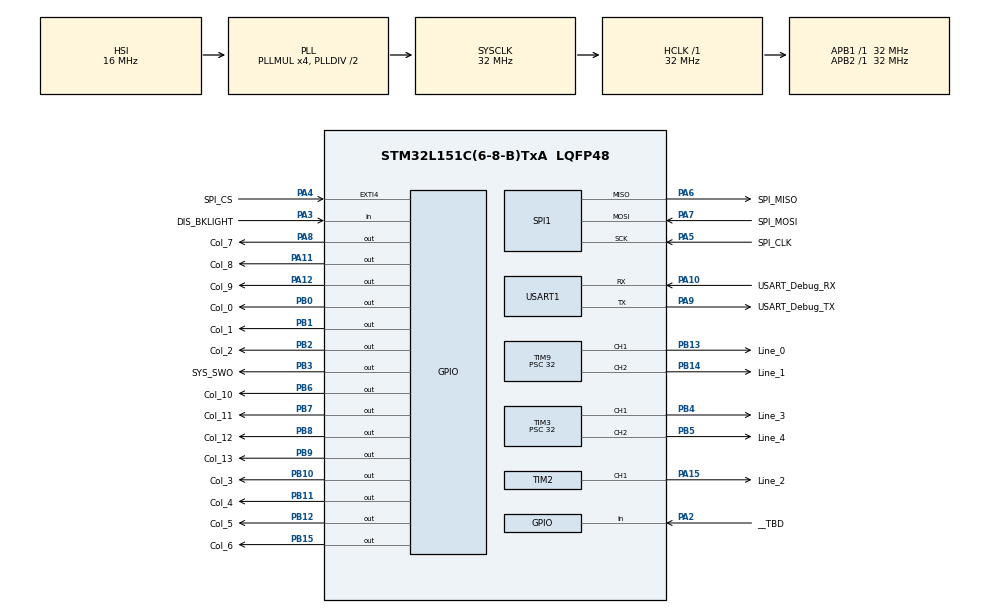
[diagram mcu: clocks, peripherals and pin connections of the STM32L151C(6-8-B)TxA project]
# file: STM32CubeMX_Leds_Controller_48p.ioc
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Dma.Request0=SPI1_RX
Dma.SPI1_RX.0.Direction=DMA_PERIPH_TO_MEMORY
Dma.SPI1_RX.0.Instance=DMA1_Channel2
Dma.SPI1_RX.0.MemDataAlignment=DMA_MDATAALIGN_BYTE
Dma.SPI1_RX.0.MemInc=DMA_MINC_ENABLE
Dma.SPI1_RX.0.Mode=DMA_NORMAL
Dma.SPI1_RX.0.PeriphDataAlignment=DMA_PDATAALIGN_BYTE
Dma.SPI1_RX.0.PeriphInc=DMA_PINC_DISABLE
Dma.SPI1_RX.0.Priority=DMA_PRIORITY_MEDIUM
FREERTOS.HEAP_NUMBER=1
FREERTOS.Mutexes01=MtxLedMatrix;MtxCRC32
FREERTOS.Tasks01=MultiplexTask,0,64,StartMultiplexTask,As weak;GraphicTask,-1,128,StartGraphicTask,As weak;CommTask,0,64,StartCommTask,As weak
FREERTOS.configENABLE_BACKWARD_COMPATIBILITY=0
FREERTOS.configMINIMAL_STACK_SIZE=64
FREERTOS.configQUEUE_REGISTRY_SIZE=0
FREERTOS.configUSE_MUTEXES=1
FREERTOS.configUSE_PORT_OPTIMISED_TASK_SELECTION=0
FREERTOS.configUSE_TASK_NOTIFICATIONS=1
FREERTOS.configUSE_TRACE_FACILITY=0
Mcu.Family=STM32L1
Mcu.Name=STM32L151C(6-8-B)TxA
Mcu.Package=LQFP48
NVIC.DMA1_Channel2_IRQn=true\:5\:0\:false\:false\:true\:true
NVIC.EXTI4_IRQn=true\:5\:0\:false\:false\:true\:true
NVIC.PriorityGroup=NVIC_PRIORITYGROUP_4
NVIC.TIM6_IRQn=true\:0\:0\:false\:false\:true\:false
NVIC.TimeBase=TIM6_IRQn
NVIC.TimeBaseIP=TIM6
PA10.GPIO_Label=USART_Debug_RX
PA10.Mode=Asynchronous
PA10.Signal=USART1_RX
PA11.GPIO_Label=Col_8
PA11.GPIO_ModeDefaultOutputPP=GPIO_MODE_OUTPUT_OD
PA11.GPIO_Speed=GPIO_SPEED_FREQ_VERY_HIGH
PA11.PinState=GPIO_PIN_SET
PA11.Signal=GPIO_Output
PA12.GPIO_Label=Col_9
PA12.GPIO_ModeDefaultOutputPP=GPIO_MODE_OUTPUT_OD
PA12.GPIO_Speed=GPIO_SPEED_FREQ_VERY_HIGH
PA12.PinState=GPIO_PIN_SET
PA12.Signal=GPIO_Output
PA13.GPIO_Label=SYS_SWDIO
PA13.Mode=Serial_Wire
PA13.Signal=SYS_JTMS-SWDIO
PA14.GPIO_Label=SYS_SWCLK
PA14.Mode=Serial_Wire
PA14.Signal=SYS_JTCK-SWCLK
PA15.GPIO_Label=Line_2
PA15.GPIO_Speed=GPIO_SPEED_FREQ_VERY_HIGH
PA15.Signal=S_TIM2_CH1_ETR
PA2.GPIO_Label=__TBD
PA2.GPIO_Mode=GPIO_MODE_INPUT
PA2.GPIO_PuPd=GPIO_PULLDOWN
PA2.Signal=GPIO_Input
PA3.GPIO_Label=DIS_BKLIGHT
PA3.GPIO_Mode=GPIO_MODE_INPUT
PA3.GPIO_PuPd=GPIO_PULLDOWN
PA3.Signal=GPIO_Input
PA4.GPIO_Label=SPI_CS
PA4.GPIO_ModeDefaultEXTI=GPIO_MODE_IT_RISING_FALLING
PA4.Signal=GPXTI4
PA5.GPIO_Label=SPI_CLK
PA5.Mode=Full_Duplex_Slave
PA5.Signal=SPI1_SCK
PA6.GPIO_Label=SPI_MISO
PA6.Mode=Full_Duplex_Slave
PA6.Signal=SPI1_MISO
PA7.GPIO_Label=SPI_MOSI
PA7.Mode=Full_Duplex_Slave
PA7.Signal=SPI1_MOSI
PA8.GPIO_Label=Col_7
PA8.GPIO_ModeDefaultOutputPP=GPIO_MODE_OUTPUT_OD
PA8.GPIO_Speed=GPIO_SPEED_FREQ_VERY_HIGH
PA8.PinState=GPIO_PIN_SET
PA8.Signal=GPIO_Output
PA9.GPIO_Label=USART_Debug_TX
PA9.Mode=Asynchronous
PA9.Signal=USART1_TX
PB0.GPIO_Label=Col_0
PB0.GPIO_ModeDefaultOutputPP=GPIO_MODE_OUTPUT_OD
PB0.GPIO_Speed=GPIO_SPEED_FREQ_VERY_HIGH
PB0.PinState=GPIO_PIN_SET
PB0.Signal=GPIO_Output
PB1.GPIO_Label=Col_1
PB1.GPIO_ModeDefaultOutputPP=GPIO_MODE_OUTPUT_OD
PB1.GPIO_Speed=GPIO_SPEED_FREQ_VERY_HIGH
PB1.PinState=GPIO_PIN_SET
PB1.Signal=GPIO_Output
PB10.GPIO_Label=Col_3
PB10.GPIO_ModeDefaultOutputPP=GPIO_MODE_OUTPUT_OD
PB10.GPIO_Speed=GPIO_SPEED_FREQ_VERY_HIGH
PB10.PinState=GPIO_PIN_SET
PB10.Signal=GPIO_Output
PB11.GPIO_Label=Col_4
PB11.GPIO_ModeDefaultOutputPP=GPIO_MODE_OUTPUT_OD
PB11.GPIO_Speed=GPIO_SPEED_FREQ_VERY_HIGH
PB11.PinState=GPIO_PIN_SET
PB11.Signal=GPIO_Output
PB12.GPIO_Label=Col_5
PB12.GPIO_ModeDefaultOutputPP=GPIO_MODE_OUTPUT_OD
PB12.GPIO_Speed=GPIO_SPEED_FREQ_VERY_HIGH
PB12.PinState=GPIO_PIN_SET
PB12.Signal=GPIO_Output
PB13.GPIO_Label=Line_0
PB13.GPIO_Speed=GPIO_SPEED_FREQ_VERY_HIGH
PB13.Signal=S_TIM9_CH1
PB14.GPIO_Label=Line_1
PB14.GPIO_Speed=GPIO_SPEED_FREQ_VERY_HIGH
PB14.Signal=S_TIM9_CH2
PB15.GPIO_Label=Col_6
PB15.GPIO_ModeDefaultOutputPP=GPIO_MODE_OUTPUT_OD
PB15.GPIO_Speed=GPIO_SPEED_FREQ_VERY_HIGH
PB15.PinState=GPIO_PIN_SET
PB15.Signal=GPIO_Output
PB2.GPIO_Label=Col_2
PB2.GPIO_ModeDefaultOutputPP=GPIO_MODE_OUTPUT_OD
PB2.GPIO_Speed=GPIO_SPEED_FREQ_VERY_HIGH
PB2.PinState=GPIO_PIN_SET
PB2.Signal=GPIO_Output
PB3.GPIO_Label=SYS_SWO
PB3.Signal=GPIO_Output
PB4.GPIO_Label=Line_3
PB4.GPIO_Speed=GPIO_SPEED_FREQ_VERY_HIGH
PB4.Signal=S_TIM3_CH1
PB5.GPIO_Label=Line_4
PB5.GPIO_Speed=GPIO_SPEED_FREQ_VERY_HIGH
PB5.Signal=S_TIM3_CH2
PB6.GPIO_Label=Col_10
PB6.GPIO_ModeDefaultOutputPP=GPIO_MODE_OUTPUT_OD
PB6.GPIO_Speed=GPIO_SPEED_FREQ_VERY_HIGH
PB6.PinState=GPIO_PIN_SET
PB6.Signal=GPIO_Output
PB7.GPIO_Label=Col_11
PB7.GPIO_ModeDefaultOutputPP=GPIO_MODE_OUTPUT_OD
PB7.GPIO_Speed=GPIO_SPEED_FREQ_VERY_HIGH
PB7.PinState=GPIO_PIN_SET
PB7.Signal=GPIO_Output
PB8.GPIO_Label=Col_12
PB8.GPIO_ModeDefaultOutputPP=GPIO_MODE_OUTPUT_OD
PB8.GPIO_Speed=GPIO_SPEED_FREQ_VERY_HIGH
PB8.PinState=GPIO_PIN_SET
PB8.Signal=GPIO_Output
PB9.GPIO_Label=Col_13
PB9.GPIO_ModeDefaultOutputPP=GPIO_MODE_OUTPUT_OD
PB9.GPIO_Speed=GPIO_SPEED_FREQ_VERY_HIGH
PB9.PinState=GPIO_PIN_SET
PB9.Signal=GPIO_Output
ProjectManager.HeapSize=0x0
ProjectManager.StackSize=0x400
ProjectManager.TargetToolchain=TrueSTUDIO
RCC.AHBFreq_Value=32000000
RCC.APB1Freq_Value=32000000
RCC.APB1TimFreq_Value=32000000
RCC.APB2Freq_Value=32000000
RCC.APB2TimFreq_Value=32000000
RCC.HCLKFreq_Value=32000000
RCC.HSE_VALUE=24000000
RCC.HSI_VALUE=16000000
RCC.LSE_VALUE=32768
RCC.MSI_VALUE=2097000
RCC.PLLMUL=RCC_PLL_MUL4
RCC.SYSCLKFreq_VALUE=32000000
RCC.SYSCLKSource=RCC_SYSCLKSOURCE_PLLCLK
RCC.USBOutput=32000000
RCC.VCOOutputFreq_Value=64000000
SH.S_TIM2_CH1_ETR.0=TIM2_CH1,PWM Generation1 CH1
SH.S_TIM3_CH1.0=TIM3_CH1,PWM Generation1 CH1
SH.S_TIM3_CH2.0=TIM3_CH2,PWM Generation2 CH2
SH.S_TIM9_CH1.0=TIM9_CH1,PWM Generation1 CH1
SH.S_TIM9_CH2.0=TIM9_CH2,PWM Generation2 CH2
SPI1.VirtualType=VM_SLAVE
TIM2.Period=100
TIM2.Prescaler=32
TIM2.Pulse-PWM\ Generation1\ CH1=0
TIM3.Channel-PWM\ Generation2\ CH2=TIM_CHANNEL_2
TIM3.Period=100
TIM3.Prescaler=32
TIM3.Pulse-PWM\ Generation1\ CH1=0
TIM3.Pulse-PWM\ Generation2\ CH2=0
TIM9.Channel-PWM\ Generation2\ CH2=TIM_CHANNEL_2
TIM9.Period=100
TIM9.Prescaler=32
TIM9.Pulse-PWM\ Generation1\ CH1=0
TIM9.Pulse-PWM\ Generation2\ CH2=0
VP_CRC_VS_CRC.Mode=CRC_Activate
VP_FREERTOS_VS_ENABLE.Mode=Enabled
VP_SYS_VS_tim6.Mode=TIM6
VP_TIM2_VS_ClockSourceINT.Mode=Internal
VP_TIM3_VS_ClockSourceINT.Mode=Internal
VP_TIM9_VS_ClockSourceINT.Mode=Internal
board=STM32CubeMX_Leds_Controller_48p

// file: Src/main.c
/**
  ******************************************************************************
  * File Name          : main.c
  * Description        : Main program body
  ******************************************************************************
  *
  * Copyright (c) 2016 STMicroelectronics International N.V.
  * All rights reserved.
  *
  * Redistribution and use in source and binary forms, with or without
  * modification, are permitted, provided that the following conditions are met:
  *
  * 1. Redistribution of source code must retain the above copyright notice,
  *    this list of conditions and the following disclaimer.
  * 2. Redistributions in binary form must reproduce the above copyright notice,
  *    this list of conditions and the following disclaimer in the documentation
  *    and/or other materials provided with the distribution.
  * 3. Neither the name of STMicroelectronics nor the names of other
  *    contributors to this software may be used to endorse or promote products
  *    derived from this software without specific written permission.
  * 4. This software, including modifications and/or derivative works of this
  *    software, must execute solely and exclusively on microcontroller or
  *    microprocessor devices manufactured by or for STMicroelectronics.
  * 5. Redistribution and use of this software other than as permitted under
  *    this license is void and will automatically terminate your rights under
  *    this license.
  *
  * THIS SOFTWARE IS PROVIDED BY STMICROELECTRONICS AND CONTRIBUTORS "AS IS"
  * AND ANY EXPRESS, IMPLIED OR STATUTORY WARRANTIES, INCLUDING, BUT NOT
  * LIMITED TO, THE IMPLIED WARRANTIES OF MERCHANTABILITY, FITNESS FOR A
  * PARTICULAR PURPOSE AND NON-INFRINGEMENT OF THIRD PARTY INTELLECTUAL PROPERTY
  * RIGHTS ARE DISCLAIMED TO THE FULLEST EXTENT PERMITTED BY LAW. IN NO EVENT
  * SHALL STMICROELECTRONICS OR CONTRIBUTORS BE LIABLE FOR ANY DIRECT, INDIRECT,
  * INCIDENTAL, SPECIAL, EXEMPLARY, OR CONSEQUENTIAL DAMAGES (INCLUDING, BUT NOT
  * LIMITED TO, PROCUREMENT OF SUBSTITUTE GOODS OR SERVICES; LOSS OF USE, DATA,
  * OR PROFITS; OR BUSINESS INTERRUPTION) HOWEVER CAUSED AND ON ANY THEORY OF
  * LIABILITY, WHETHER IN CONTRACT, STRICT LIABILITY, OR TORT (INCLUDING
  * NEGLIGENCE OR OTHERWISE) ARISING IN ANY WAY OUT OF THE USE OF THIS SOFTWARE,
  * EVEN IF ADVISED OF THE POSSIBILITY OF SUCH DAMAGE.
  *
  ******************************************************************************
  */
#include "main.h"
#include "stm32l1xx_hal.h"
#include "cmsis_os.h"

/* USER CODE BEGIN Includes */
#include "Utils.h"
#include "Mailboxes.h"
/* USER CODE END Includes */

CRC_HandleTypeDef hcrc;

SPI_HandleTypeDef hspi1;
DMA_HandleTypeDef hdma_spi1_rx;

TIM_HandleTypeDef htim2;
TIM_HandleTypeDef htim3;
TIM_HandleTypeDef htim9;

UART_HandleTypeDef huart1;

osThreadId MultiplexTaskHandle;
osThreadId GraphicTaskHandle;
osThreadId CommTaskHandle;
osMutexId MtxLedMatrixHandle;
osMutexId MtxCRC32Handle;

/* USER CODE BEGIN PV */
/* Private variables ---------------------------------------------------------*/

/* USER CODE END PV */

void SystemClock_Config(void);
void Error_Handler(void);
static void MX_GPIO_Init(void);
static void MX_DMA_Init(void);
static void MX_SPI1_Init(void);
static void MX_USART1_UART_Init(void);
static void MX_TIM2_Init(void);
static void MX_TIM3_Init(void);
static void MX_TIM9_Init(void);
static void MX_CRC_Init(void);
void StartMultiplexTask(void const * argument);
void StartGraphicTask(void const * argument);
void StartCommTask(void const * argument);

void HAL_TIM_MspPostInit(TIM_HandleTypeDef *htim);

/* USER CODE BEGIN PFP */
/* Private function prototypes -----------------------------------------------*/

/* USER CODE END PFP */

int main(void)
{

  /* USER CODE BEGIN 1 */
  Utils_Init();
  /* USER CODE END 1 */

  /* MCU Configuration----------------------------------------------------------*/

  /* Reset of all peripherals, Initializes the Flash interface and the Systick. */
  HAL_Init();

  /* Configure the system clock */
  SystemClock_Config();

  /* Initialize all configured peripherals */
  MX_GPIO_Init();
  MX_DMA_Init();
  MX_SPI1_Init();
  MX_USART1_UART_Init();
  MX_TIM2_Init();
  MX_TIM3_Init();
  MX_TIM9_Init();
  MX_CRC_Init();

  /* USER CODE BEGIN 2 */
  //Create Mailboxes
  TCKB_Init_SERIAL_Mailbox();
  /* USER CODE END 2 */

  /* Create the mutex(es) */
  /* definition and creation of MtxLedMatrix */
  osMutexDef(MtxLedMatrix);
  MtxLedMatrixHandle = osMutexCreate(osMutex(MtxLedMatrix));

  /* definition and creation of MtxCRC32 */
  osMutexDef(MtxCRC32);
  MtxCRC32Handle = osMutexCreate(osMutex(MtxCRC32));

  /* Create the thread(s) */
  /* definition and creation of MultiplexTask */
  osThreadDef(MultiplexTask, StartMultiplexTask, osPriorityNormal, 0, 64);
  MultiplexTaskHandle = osThreadCreate(osThread(MultiplexTask), NULL);

  /* definition and creation of GraphicTask */
  osThreadDef(GraphicTask, StartGraphicTask, osPriorityBelowNormal, 0, 128);
  GraphicTaskHandle = osThreadCreate(osThread(GraphicTask), NULL);

  /* definition and creation of CommTask */
  osThreadDef(CommTask, StartCommTask, osPriorityNormal, 0, 64);
  CommTaskHandle = osThreadCreate(osThread(CommTask), NULL);

  /* Start scheduler */
  osKernelStart();

  /* We should never get here as control is now taken by the scheduler */

  /* Infinite loop */
  while (1)
  {

  }

}

/** System Clock Configuration
*/
void SystemClock_Config(void)
{

  RCC_OscInitTypeDef RCC_OscInitStruct;
  RCC_ClkInitTypeDef RCC_ClkInitStruct;

    /**Configure the main internal regulator output voltage
    */
  __HAL_PWR_VOLTAGESCALING_CONFIG(PWR_REGULATOR_VOLTAGE_SCALE1);

    /**Initializes the CPU, AHB and APB busses clocks
    */
  RCC_OscInitStruct.OscillatorType = RCC_OSCILLATORTYPE_HSI;
  RCC_OscInitStruct.HSIState = RCC_HSI_ON;
  RCC_OscInitStruct.HSICalibrationValue = 16;
  RCC_OscInitStruct.PLL.PLLState = RCC_PLL_ON;
  RCC_OscInitStruct.PLL.PLLSource = RCC_PLLSOURCE_HSI;
  RCC_OscInitStruct.PLL.PLLMUL = RCC_PLL_MUL4;
  RCC_OscInitStruct.PLL.PLLDIV = RCC_PLL_DIV2;
  if (HAL_RCC_OscConfig(&RCC_OscInitStruct) != HAL_OK)
  {
    Error_Handler();
  }

    /**Initializes the CPU, AHB and APB busses clocks
    */
  RCC_ClkInitStruct.ClockType = RCC_CLOCKTYPE_HCLK|RCC_CLOCKTYPE_SYSCLK
                              |RCC_CLOCKTYPE_PCLK1|RCC_CLOCKTYPE_PCLK2;
  RCC_ClkInitStruct.SYSCLKSource = RCC_SYSCLKSOURCE_PLLCLK;
  RCC_ClkInitStruct.AHBCLKDivider = RCC_SYSCLK_DIV1;
  RCC_ClkInitStruct.APB1CLKDivider = RCC_HCLK_DIV1;
  RCC_ClkInitStruct.APB2CLKDivider = RCC_HCLK_DIV1;

  if (HAL_RCC_ClockConfig(&RCC_ClkInitStruct, FLASH_LATENCY_1) != HAL_OK)
  {
    Error_Handler();
  }

    /**Configure the Systick interrupt time
    */
  HAL_SYSTICK_Config(HAL_RCC_GetHCLKFreq()/1000);

    /**Configure the Systick
    */
  HAL_SYSTICK_CLKSourceConfig(SYSTICK_CLKSOURCE_HCLK);

  /* SysTick_IRQn interrupt configuration */
  HAL_NVIC_SetPriority(SysTick_IRQn, 15, 0);
}

/* CRC init function */
static void MX_CRC_Init(void)
{

  hcrc.Instance = CRC;
  if (HAL_CRC_Init(&hcrc) != HAL_OK)
  {
    Error_Handler();
  }

}

/* SPI1 init function */
static void MX_SPI1_Init(void)
{

  hspi1.Instance = SPI1;
  hspi1.Init.Mode = SPI_MODE_SLAVE;
  hspi1.Init.Direction = SPI_DIRECTION_2LINES;
  hspi1.Init.DataSize = SPI_DATASIZE_8BIT;
  hspi1.Init.CLKPolarity = SPI_POLARITY_LOW;
  hspi1.Init.CLKPhase = SPI_PHASE_1EDGE;
  hspi1.Init.NSS = SPI_NSS_SOFT;
  hspi1.Init.FirstBit = SPI_FIRSTBIT_MSB;
  hspi1.Init.TIMode = SPI_TIMODE_DISABLE;
  hspi1.Init.CRCCalculation = SPI_CRCCALCULATION_DISABLE;
  hspi1.Init.CRCPolynomial = 10;
  if (HAL_SPI_Init(&hspi1) != HAL_OK)
  {
    Error_Handler();
  }

}

/* TIM2 init function */
static void MX_TIM2_Init(void)
{

  TIM_ClockConfigTypeDef sClockSourceConfig;
  TIM_MasterConfigTypeDef sMasterConfig;
  TIM_OC_InitTypeDef sConfigOC;

  htim2.Instance = TIM2;
  htim2.Init.Prescaler = 32;
  htim2.Init.CounterMode = TIM_COUNTERMODE_UP;
  htim2.Init.Period = 100;
  htim2.Init.ClockDivision = TIM_CLOCKDIVISION_DIV1;
  if (HAL_TIM_Base_Init(&htim2) != HAL_OK)
  {
    Error_Handler();
  }

  sClockSourceConfig.ClockSource = TIM_CLOCKSOURCE_INTERNAL;
  if (HAL_TIM_ConfigClockSource(&htim2, &sClockSourceConfig) != HAL_OK)
  {
    Error_Handler();
  }

  if (HAL_TIM_PWM_Init(&htim2) != HAL_OK)
  {
    Error_Handler();
  }

  sMasterConfig.MasterOutputTrigger = TIM_TRGO_RESET;
  sMasterConfig.MasterSlaveMode = TIM_MASTERSLAVEMODE_DISABLE;
  if (HAL_TIMEx_MasterConfigSynchronization(&htim2, &sMasterConfig) != HAL_OK)
  {
    Error_Handler();
  }

  sConfigOC.OCMode = TIM_OCMODE_PWM1;
  sConfigOC.Pulse = 0;
  sConfigOC.OCPolarity = TIM_OCPOLARITY_HIGH;
  sConfigOC.OCFastMode = TIM_OCFAST_DISABLE;
  if (HAL_TIM_PWM_ConfigChannel(&htim2, &sConfigOC, TIM_CHANNEL_1) != HAL_OK)
  {
    Error_Handler();
  }

  HAL_TIM_MspPostInit(&htim2);

}

/* TIM3 init function */
static void MX_TIM3_Init(void)
{

  TIM_ClockConfigTypeDef sClockSourceConfig;
  TIM_MasterConfigTypeDef sMasterConfig;
  TIM_OC_InitTypeDef sConfigOC;

  htim3.Instance = TIM3;
  htim3.Init.Prescaler = 32;
  htim3.Init.CounterMode = TIM_COUNTERMODE_UP;
  htim3.Init.Period = 100;
  htim3.Init.ClockDivision = TIM_CLOCKDIVISION_DIV1;
  if (HAL_TIM_Base_Init(&htim3) != HAL_OK)
  {
    Error_Handler();
  }

  sClockSourceConfig.ClockSource = TIM_CLOCKSOURCE_INTERNAL;
  if (HAL_TIM_ConfigClockSource(&htim3, &sClockSourceConfig) != HAL_OK)
  {
    Error_Handler();
  }

  if (HAL_TIM_PWM_Init(&htim3) != HAL_OK)
  {
    Error_Handler();
  }

  sMasterConfig.MasterOutputTrigger = TIM_TRGO_RESET;
  sMasterConfig.MasterSlaveMode = TIM_MASTERSLAVEMODE_DISABLE;
  if (HAL_TIMEx_MasterConfigSynchronization(&htim3, &sMasterConfig) != HAL_OK)
  {
    Error_Handler();
  }

  sConfigOC.OCMode = TIM_OCMODE_PWM1;
  sConfigOC.Pulse = 0;
  sConfigOC.OCPolarity = TIM_OCPOLARITY_HIGH;
  sConfigOC.OCFastMode = TIM_OCFAST_DISABLE;
  if (HAL_TIM_PWM_ConfigChannel(&htim3, &sConfigOC, TIM_CHANNEL_1) != HAL_OK)
  {
    Error_Handler();
  }

  if (HAL_TIM_PWM_ConfigChannel(&htim3, &sConfigOC, TIM_CHANNEL_2) != HAL_OK)
  {
    Error_Handler();
  }

  HAL_TIM_MspPostInit(&htim3);

}

/* TIM9 init function */
static void MX_TIM9_Init(void)
{

  TIM_ClockConfigTypeDef sClockSourceConfig;
  TIM_MasterConfigTypeDef sMasterConfig;
  TIM_OC_InitTypeDef sConfigOC;

  htim9.Instance = TIM9;
  htim9.Init.Prescaler = 32;
  htim9.Init.CounterMode = TIM_COUNTERMODE_UP;
  htim9.Init.Period = 100;
  htim9.Init.ClockDivision = TIM_CLOCKDIVISION_DIV1;
  if (HAL_TIM_Base_Init(&htim9) != HAL_OK)
  {
    Error_Handler();
  }

  sClockSourceConfig.ClockSource = TIM_CLOCKSOURCE_INTERNAL;
  if (HAL_TIM_ConfigClockSource(&htim9, &sClockSourceConfig) != HAL_OK)
  {
    Error_Handler();
  }

  if (HAL_TIM_PWM_Init(&htim9) != HAL_OK)
  {
    Error_Handler();
  }

  sMasterConfig.MasterOutputTrigger = TIM_TRGO_RESET;
  sMasterConfig.MasterSlaveMode = TIM_MASTERSLAVEMODE_DISABLE;
  if (HAL_TIMEx_MasterConfigSynchronization(&htim9, &sMasterConfig) != HAL_OK)
  {
    Error_Handler();
  }

  sConfigOC.OCMode = TIM_OCMODE_PWM1;
  sConfigOC.Pulse = 0;
  sConfigOC.OCPolarity = TIM_OCPOLARITY_HIGH;
  sConfigOC.OCFastMode = TIM_OCFAST_DISABLE;
  if (HAL_TIM_PWM_ConfigChannel(&htim9, &sConfigOC, TIM_CHANNEL_1) != HAL_OK)
  {
    Error_Handler();
  }

  if (HAL_TIM_PWM_ConfigChannel(&htim9, &sConfigOC, TIM_CHANNEL_2) != HAL_OK)
  {
    Error_Handler();
  }

  HAL_TIM_MspPostInit(&htim9);

}

/* USART1 init function */
static void MX_USART1_UART_Init(void)
{

  huart1.Instance = USART1;
  huart1.Init.BaudRate = 115200;
  huart1.Init.WordLength = UART_WORDLENGTH_8B;
  huart1.Init.StopBits = UART_STOPBITS_1;
  huart1.Init.Parity = UART_PARITY_NONE;
  huart1.Init.Mode = UART_MODE_TX_RX;
  huart1.Init.HwFlowCtl = UART_HWCONTROL_NONE;
  huart1.Init.OverSampling = UART_OVERSAMPLING_16;
  if (HAL_UART_Init(&huart1) != HAL_OK)
  {
    Error_Handler();
  }

}

static void MX_DMA_Init(void)
{
  /* DMA controller clock enable */
  __HAL_RCC_DMA1_CLK_ENABLE();

  /* DMA interrupt init */
  /* DMA1_Channel2_IRQn interrupt configuration */
  HAL_NVIC_SetPriority(DMA1_Channel2_IRQn, 5, 0);
  HAL_NVIC_EnableIRQ(DMA1_Channel2_IRQn);

}

/** Configure pins as
        * Analog
        * Input
        * Output
        * EVENT_OUT
        * EXTI
*/
static void MX_GPIO_Init(void)
{

  GPIO_InitTypeDef GPIO_InitStruct;

  /* GPIO Ports Clock Enable */
  __HAL_RCC_GPIOA_CLK_ENABLE();
  __HAL_RCC_GPIOB_CLK_ENABLE();

  /*Configure GPIO pins : __TBD_Pin DIS_BKLIGHT_Pin */
  GPIO_InitStruct.Pin = __TBD_Pin|DIS_BKLIGHT_Pin;
  GPIO_InitStruct.Mode = GPIO_MODE_INPUT;
  GPIO_InitStruct.Pull = GPIO_PULLDOWN;
  HAL_GPIO_Init(GPIOA, &GPIO_InitStruct);

  /*Configure GPIO pin : SPI_CS_Pin */
  GPIO_InitStruct.Pin = SPI_CS_Pin;
  GPIO_InitStruct.Mode = GPIO_MODE_IT_RISING_FALLING;
  GPIO_InitStruct.Pull = GPIO_NOPULL;
  HAL_GPIO_Init(SPI_CS_GPIO_Port, &GPIO_InitStruct);

  /*Configure GPIO pins : Col_0_Pin Col_1_Pin Col_2_Pin Col_3_Pin
                           Col_4_Pin Col_5_Pin Col_6_Pin Col_10_Pin
                           Col_11_Pin Col_12_Pin Col_13_Pin */
  GPIO_InitStruct.Pin = Col_0_Pin|Col_1_Pin|Col_2_Pin|Col_3_Pin
                          |Col_4_Pin|Col_5_Pin|Col_6_Pin|Col_10_Pin
                          |Col_11_Pin|Col_12_Pin|Col_13_Pin;
  GPIO_InitStruct.Mode = GPIO_MODE_OUTPUT_OD;
  GPIO_InitStruct.Pull = GPIO_NOPULL;
  GPIO_InitStruct.Speed = GPIO_SPEED_FREQ_VERY_HIGH;
  HAL_GPIO_Init(GPIOB, &GPIO_InitStruct);

  /*Configure GPIO pins : Col_7_Pin Col_8_Pin Col_9_Pin */
  GPIO_InitStruct.Pin = Col_7_Pin|Col_8_Pin|Col_9_Pin;
  GPIO_InitStruct.Mode = GPIO_MODE_OUTPUT_OD;
  GPIO_InitStruct.Pull = GPIO_NOPULL;
  GPIO_InitStruct.Speed = GPIO_SPEED_FREQ_VERY_HIGH;
  HAL_GPIO_Init(GPIOA, &GPIO_InitStruct);

  /*Configure GPIO pin : SYS_SWO_Pin */
  GPIO_InitStruct.Pin = SYS_SWO_Pin;
  GPIO_InitStruct.Mode = GPIO_MODE_OUTPUT_PP;
  GPIO_InitStruct.Pull = GPIO_NOPULL;
  GPIO_InitStruct.Speed = GPIO_SPEED_FREQ_LOW;
  HAL_GPIO_Init(SYS_SWO_GPIO_Port, &GPIO_InitStruct);

  /*Configure GPIO pin Output Level */
  HAL_GPIO_WritePin(GPIOB, Col_0_Pin|Col_1_Pin|Col_2_Pin|Col_3_Pin
                          |Col_4_Pin|Col_5_Pin|Col_6_Pin|Col_10_Pin
                          |Col_11_Pin|Col_12_Pin|Col_13_Pin, GPIO_PIN_SET);

  /*Configure GPIO pin Output Level */
  HAL_GPIO_WritePin(GPIOA, Col_7_Pin|Col_8_Pin|Col_9_Pin, GPIO_PIN_SET);

  /*Configure GPIO pin Output Level */
  HAL_GPIO_WritePin(SYS_SWO_GPIO_Port, SYS_SWO_Pin, GPIO_PIN_RESET);

  /* EXTI interrupt init*/
  HAL_NVIC_SetPriority(EXTI4_IRQn, 5, 0);
  HAL_NVIC_EnableIRQ(EXTI4_IRQn);

}

/* StartMultiplexTask function */
__weak void StartMultiplexTask(void const * argument)
{

  for(;;)
  {
    osDelay(1);
  }
}

/* StartGraphicTask function */
__weak void StartGraphicTask(void const * argument)
{
  for(;;)
  {
    osDelay(1);
  }
}

/* StartCommTask function */
__weak void StartCommTask(void const * argument)
{
  for(;;)
  {
    osDelay(1);
  }
}

void HAL_TIM_PeriodElapsedCallback(TIM_HandleTypeDef *htim)
{
  if (htim->Instance == TIM6) {
    HAL_IncTick();
  }
}

void Error_Handler(void)
{
  while(1)
  {
  }
}

/************************ (C) COPYRIGHT STMicroelectronics *****END OF FILE****/
